VERSION ""

NS_ :

BS_:

BU_: NEO MCU GTW EPAS DI ESP SBW STW

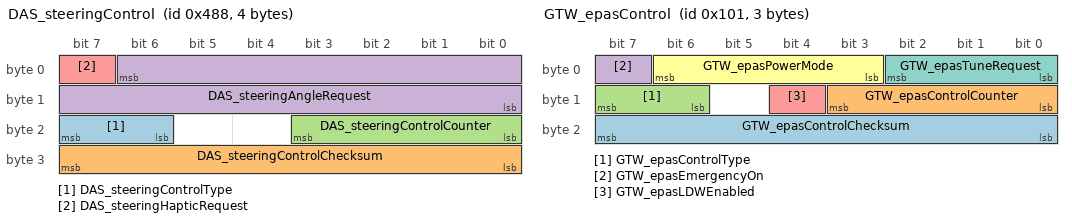
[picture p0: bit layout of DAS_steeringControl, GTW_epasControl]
BO_ 1160 DAS_steeringControl: 4 NEO
 SG_ DAS_steeringControlType : 23|2@0+ (1,0) [0|0] "" EPAS
 SG_ DAS_steeringControlChecksum : 31|8@0+ (1,0) [0|0] "" EPAS
 SG_ DAS_steeringControlCounter : 19|4@0+ (1,0) [0|0] "" EPAS
 SG_ DAS_steeringAngleRequest : 6|15@0+ (0.1,-1638.35) [-1638.35|1638.35] "deg" EPAS
 SG_ DAS_steeringHapticRequest : 7|1@0+ (1,0) [0|0] "" EPAS

BO_ 257 GTW_epasControl: 3 NEO
 SG_ GTW_epasControlChecksum : 23|8@0+ (1,0) [0|255] ""  NEO
 SG_ GTW_epasControlCounter : 11|4@0+ (1,0) [0|15] ""  NEO
 SG_ GTW_epasControlType : 15|2@0+ (1,0) [-1|4] ""  NEO
 SG_ GTW_epasEmergencyOn : 7|1@0+ (1,0) [-1|2] ""  NEO
 SG_ GTW_epasLDWEnabled : 12|1@0+ (1,0) [-1|2] ""  NEO
 SG_ GTW_epasPowerMode : 6|4@0+ (1,0) [4|14] ""  NEO
 SG_ GTW_epasTuneRequest : 2|3@0+ (1,0) [-1|8] ""  NEO

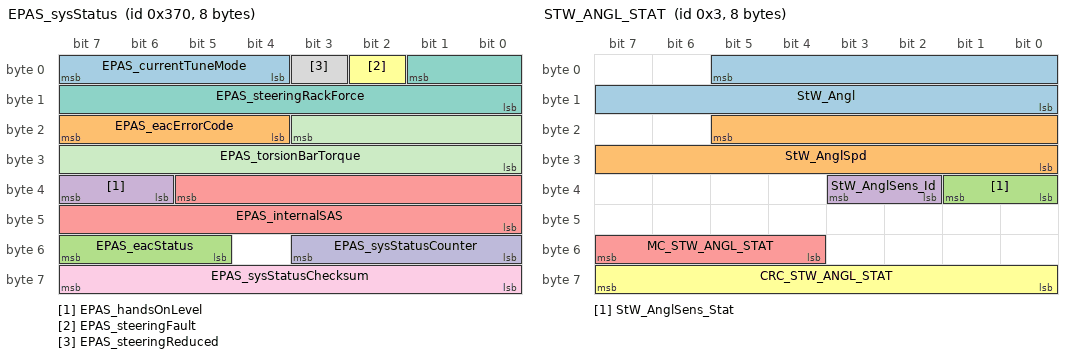
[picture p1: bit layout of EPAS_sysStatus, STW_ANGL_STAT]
BO_ 880 EPAS_sysStatus: 8 EPAS
 SG_ EPAS_currentTuneMode : 7|4@0+ (1,0) [8|15] ""  NEO
 SG_ EPAS_eacErrorCode : 23|4@0+ (1,0) [-1|16] ""  NEO
 SG_ EPAS_eacStatus : 55|3@0+ (1,0) [5|7] ""  NEO
 SG_ EPAS_handsOnLevel : 39|2@0+ (1,0) [-1|4] ""  NEO
 SG_ EPAS_internalSAS : 37|14@0+ (0.1,-819.200012) [0|0] "deg"  NEO
 SG_ EPAS_steeringFault : 2|1@0+ (1,0) [-1|2] ""  NEO
 SG_ EPAS_steeringRackForce : 1|10@0+ (50,-25575) [0|0] "N" NEO
 SG_ EPAS_steeringReduced : 3|1@0+ (1,0) [-1|2] ""  NEO
 SG_ EPAS_sysStatusChecksum : 63|8@0+ (1,0) [0|255] ""  NEO
 SG_ EPAS_sysStatusCounter : 51|4@0+ (1,0) [0|15] ""  NEO
 SG_ EPAS_torsionBarTorque : 19|12@0+ (0.01,-20.5) [0|0] "Nm"  NEO

BO_ 3 STW_ANGL_STAT: 8 STW
 SG_ StW_Angl : 5|14@0+ (0.5,-2048) [0|0] "deg"  NEO
 SG_ StW_AnglSpd : 21|14@0+ (0.5,-2048) [0|0] "/s"  NEO
 SG_ StW_AnglSens_Stat : 33|2@0+ (1,0) [-1|4] ""  NEO
 SG_ StW_AnglSens_Id : 35|2@0+ (1,0) [3|3] ""  NEO
 SG_ MC_STW_ANGL_STAT : 55|4@0+ (1,0) [0|15] ""  NEO
 SG_ CRC_STW_ANGL_STAT : 63|8@0+ (1,0) [0|255] ""  NEO

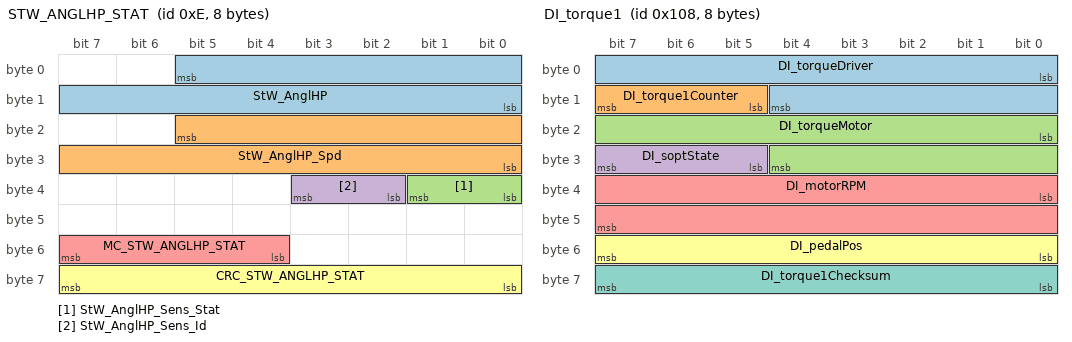
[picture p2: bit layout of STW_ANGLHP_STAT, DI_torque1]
BO_ 14 STW_ANGLHP_STAT: 8 STW
 SG_ StW_AnglHP : 5|14@0+ (0.1,-819.2) [-819.2|819] "deg"  NEO
 SG_ StW_AnglHP_Spd : 21|14@0+ (0.5,-4096) [-4096|4095.5] "deg/s"  NEO
 SG_ StW_AnglHP_Sens_Stat : 33|2@0+ (1,0) [0|0] ""  NEO
 SG_ StW_AnglHP_Sens_Id : 35|2@0+ (1,0) [0|0] ""  NEO
 SG_ MC_STW_ANGLHP_STAT : 55|4@0+ (1,0) [0|15] ""  NEO
 SG_ CRC_STW_ANGLHP_STAT : 63|8@0+ (1,0) [0|0] ""  NEO

BO_ 264 DI_torque1: 8 DI
 SG_ DI_torqueDriver : 0|13@1- (0.25,0) [-750|750] "Nm"  NEO
 SG_ DI_torque1Counter : 13|3@1+ (1,0) [0|0] ""  NEO
 SG_ DI_torqueMotor : 16|13@1- (0.25,0) [-750|750] "Nm"  NEO
 SG_ DI_soptState : 29|3@1+ (1,0) [0|0] ""  NEO
 SG_ DI_motorRPM : 32|16@1- (1,0) [-17000|17000] "RPM"  NEO
 SG_ DI_pedalPos : 48|8@1+ (0.4,0) [0|100] "%"  NEO
 SG_ DI_torque1Checksum : 56|8@1+ (1,0) [0|0] ""  NEO

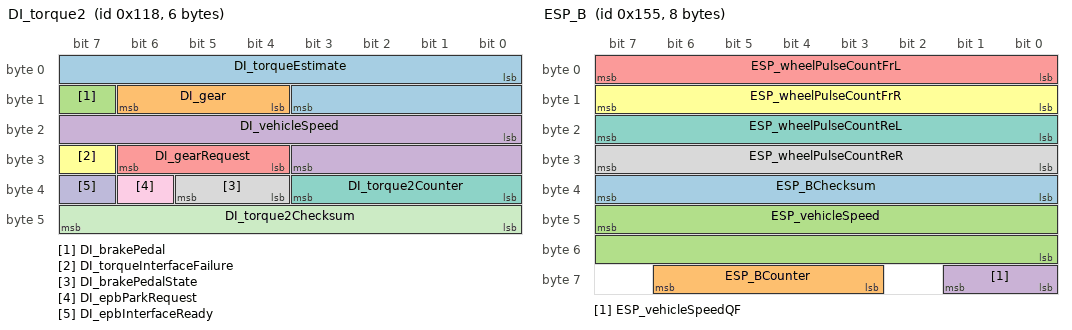
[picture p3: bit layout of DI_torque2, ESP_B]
BO_ 280 DI_torque2: 6 DI
 SG_ DI_torqueEstimate : 0|12@1- (0.5,0) [-750|750] "Nm" NEO
 SG_ DI_gear : 12|3@1+ (1,0) [0|0] "" NEO
 SG_ DI_brakePedal : 15|1@1+ (1,0) [0|0] "" NEO
 SG_ DI_vehicleSpeed : 16|12@1+ (0.05,-25) [-25|179.75] "MPH" NEO
 SG_ DI_gearRequest : 28|3@1+ (1,0) [0|0] "" NEO
 SG_ DI_torqueInterfaceFailure : 31|1@1+ (1,0) [0|0] "" NEO
 SG_ DI_torque2Counter : 32|4@1+ (1,0) [0|0] "" NEO
 SG_ DI_brakePedalState : 36|2@1+ (1,0) [0|0] "" NEO
 SG_ DI_epbParkRequest : 38|1@1+ (1,0) [0|0] "" NEO
 SG_ DI_epbInterfaceReady : 39|1@1+ (1,0) [0|0] "" NEO
 SG_ DI_torque2Checksum : 40|8@1+ (1,0) [0|0] "" NEO

BO_ 309 ESP_135h: 5 ESP
 SG_ ESP_135hChecksum : 23|8@0+ (1,0) [0|255] ""  NEO
 SG_ ESP_135hCounter : 11|4@0+ (1,0) [0|15] ""  NEO
 SG_ ESP_absBrakeEvent : 2|1@0+ (1,0) [-1|2] ""  NEO
 SG_ ESP_brakeDiscWipingActive : 4|1@0+ (1,0) [-1|2] ""  NEO
 SG_ ESP_brakeLamp : 3|1@0+ (1,0) [-1|2] ""  NEO
 SG_ ESP_espFaultLamp : 6|1@0+ (1,0) [-1|2] ""  NEO
 SG_ ESP_espLampFlash : 7|1@0+ (1,0) [-1|2] ""  NEO
 SG_ ESP_hillStartAssistActive : 1|2@0+ (1,0) [-1|4] ""  NEO
 SG_ ESP_messagePumpService : 24|1@0+ (1,0) [0|1] ""  NEO
 SG_ ESP_messagePumpFailure : 25|1@0+ (1,0) [0|1] ""  NEO
 SG_ ESP_messageEBDFailure : 26|1@0+ (1,0) [0|1] ""  NEO
 SG_ ESP_absFaultLamp : 27|1@0+ (1,0) [-1|2] ""  NEO
 SG_ ESP_tcDisabledByFault : 28|1@0+ (1,0) [0|1] ""  NEO
 SG_ ESP_messageDynoModeActive : 29|1@0+ (1,0) [0|1] ""  NEO
 SG_ ESP_hydraulicBoostEnabled : 30|1@0+ (1,0) [0|1] ""  NEO
 SG_ ESP_espOffLamp : 31|1@0+ (1,0) [-1|2] ""  NEO
 SG_ ESP_stabilityControlSts : 14|3@0+ (1,0) [6|7] ""  NEO
 SG_ ESP_tcLampFlash : 5|1@0+ (1,0) [-1|2] ""  NEO
 SG_ ESP_tcOffLamp : 15|1@0+ (1,0) [0|1] ""  NEO

BO_ 341 ESP_B: 8 ESP
 SG_ ESP_BChecksum : 39|8@0+ (1,0) [0|255] ""  NEO,EPAS
 SG_ ESP_BCounter : 62|4@0+ (1,0) [1|15] ""  NEO,EPAS
 SG_ ESP_vehicleSpeed : 47|16@0+ (0.00999999978,0) [0|0] "kph"  NEO,EPAS
 SG_ ESP_vehicleSpeedQF : 57|2@0+ (1,0) [1|2] ""  NEO,EPAS
 SG_ ESP_wheelPulseCountFrL : 7|8@0+ (1,0) [0|254] ""  NEO,EPAS
 SG_ ESP_wheelPulseCountFrR : 15|8@0+ (1,0) [0|254] ""  NEO,EPAS
 SG_ ESP_wheelPulseCountReL : 23|8@0+ (1,0) [0|254] ""  NEO,EPAS
 SG_ ESP_wheelPulseCountReR : 31|8@0+ (1,0) [0|254] ""  NEO,EPAS

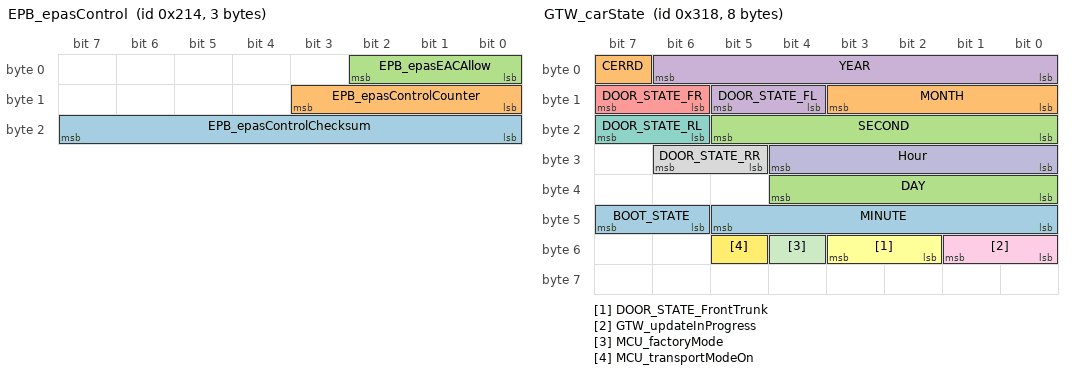
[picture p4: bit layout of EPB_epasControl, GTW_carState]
BO_ 532 EPB_epasControl: 3 EPB
 SG_ EPB_epasControlChecksum : 23|8@0+ (1,0) [0|255] ""  NEO,EPAS
 SG_ EPB_epasControlCounter : 11|4@0+ (1,0) [0|15] ""  NEO,EPAS
 SG_ EPB_epasEACAllow : 2|3@0+ (1,0) [4|7] ""  NEO,EPAS

BO_ 792 GTW_carState: 8 GTW
 SG_ BOOT_STATE : 47|2@0+ (1,0) [-1|4] ""  NEO
 SG_ CERRD : 7|1@0+ (1,0) [-1|2] ""  NEO
 SG_ DAY : 36|5@0+ (1,0) [2|31] ""  NEO
 SG_ DOOR_STATE_FL : 13|2@0+ (1,0) [-1|4] ""  NEO
 SG_ DOOR_STATE_FR : 15|2@0+ (1,0) [-1|4] ""  NEO
 SG_ DOOR_STATE_FrontTrunk : 51|2@0+ (1,0) [-1|4] ""  NEO
 SG_ DOOR_STATE_RL : 23|2@0+ (1,0) [-1|4] ""  NEO
 SG_ DOOR_STATE_RR : 30|2@0+ (1,0) [-1|4] ""  NEO
 SG_ GTW_updateInProgress : 49|2@0+ (1,0) [-1|4] ""  NEO
 SG_ Hour : 28|5@0+ (1,0) [0|29] "h"  NEO
 SG_ MCU_factoryMode : 52|1@0+ (1,0) [-1|2] ""  NEO
 SG_ MCU_transportModeOn : 53|1@0+ (1,0) [1|1] ""  NEO
 SG_ MINUTE : 45|6@0+ (1,0) [0|61] "min"  NEO
 SG_ MONTH : 11|4@0+ (1,0) [0|14] "Month"  NEO
 SG_ SECOND : 21|6@0+ (1,0) [0|61] "s"  NEO
 SG_ YEAR : 6|7@0+ (1,2000) [2000|2125] "Year"  NEO

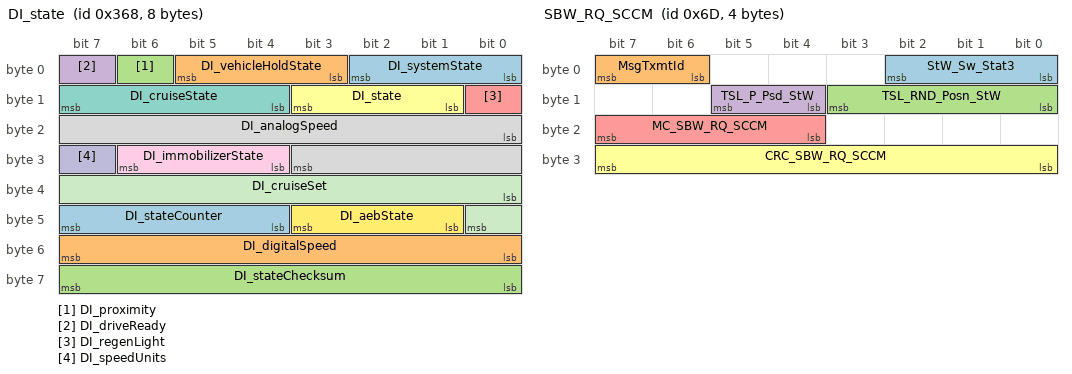
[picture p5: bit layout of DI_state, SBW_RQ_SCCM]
BO_ 872 DI_state: 8 DI
 SG_ DI_systemState : 0|3@1+ (1,0) [0|0] ""  NEO
 SG_ DI_vehicleHoldState : 3|3@1+ (1,0) [0|0] ""  NEO
 SG_ DI_proximity : 6|1@1+ (1,0) [0|0] ""  NEO
 SG_ DI_driveReady : 7|1@1+ (1,0) [0|0] ""  NEO
 SG_ DI_regenLight : 8|1@1+ (1,0) [0|0] ""  NEO
 SG_ DI_state : 9|3@1+ (1,0) [0|0] ""  NEO
 SG_ DI_cruiseState : 12|4@1+ (1,0) [0|0] ""  NEO
 SG_ DI_analogSpeed : 16|12@1+ (0.1,0) [0|150] "speed"  NEO
 SG_ DI_immobilizerState : 28|3@1+ (1,0) [0|0] ""  NEO
 SG_ DI_speedUnits : 31|1@1+ (1,0) [0|1] ""  NEO
 SG_ DI_cruiseSet : 32|9@1+ (0.5,0) [0|255.5] "speed"  NEO
 SG_ DI_aebState : 41|3@1+ (1,0) [0|0] ""  NEO
 SG_ DI_stateCounter : 44|4@1+ (1,0) [0|0] ""  NEO
 SG_ DI_digitalSpeed : 48|8@1+ (1,0) [0|250] ""  NEO
 SG_ DI_stateChecksum : 56|8@1+ (1,0) [0|0] ""  NEO

BO_ 109 SBW_RQ_SCCM: 4 STW
 SG_ StW_Sw_Stat3 : 0|3@1+ (1,0) [0|0] "" NEO
 SG_ MsgTxmtId : 6|2@1+ (1,0) [0|0] "" NEO
 SG_ TSL_RND_Posn_StW : 8|4@1+ (1,0) [0|0] "" NEO
 SG_ TSL_P_Psd_StW : 12|2@1+ (1,0) [0|0] "" NEO
 SG_ MC_SBW_RQ_SCCM : 20|4@1+ (1,0) [0|15] "" NEO
 SG_ CRC_SBW_RQ_SCCM : 24|8@1+ (1,0) [0|0] "" NEO

BO_ 69 STW_ACTN_RQ: 8 STW
 SG_ SpdCtrlLvr_Stat : 0|6@1+ (1,0) [0|0] "" NEO
 SG_ VSL_Enbl_Rq : 6|1@1+ (1,0) [0|0] "" NEO
 SG_ SpdCtrlLvrStat_Inv : 7|1@1+ (1,0) [0|0] "" NEO
 SG_ DTR_Dist_Rq : 8|8@1+ (1,0) [0|200] "" NEO
 SG_ TurnIndLvr_Stat : 16|2@1+ (1,0) [0|0] "" NEO
 SG_ HiBmLvr_Stat : 18|2@1+ (1,0) [0|0] "" NEO
 SG_ WprWashSw_Psd : 20|2@1+ (1,0) [0|0] "" NEO
 SG_ WprWash_R_Sw_Posn_V2 : 22|2@1+ (1,0) [0|0] "" NEO
 SG_ StW_Lvr_Stat : 24|3@1+ (1,0) [0|0] "" NEO
 SG_ StW_Cond_Flt : 27|1@1+ (1,0) [0|0] "" NEO
 SG_ StW_Cond_Psd : 28|2@1+ (1,0) [0|0] "" NEO
 SG_ HrnSw_Psd : 30|2@1+ (1,0) [0|0] "" NEO
 SG_ StW_Sw00_Psd : 32|1@1+ (1,0) [0|0] "" NEO
 SG_ StW_Sw01_Psd : 33|1@1+ (1,0) [0|0] "" NEO
 SG_ StW_Sw02_Psd : 34|1@1+ (1,0) [0|0] "" NEO
 SG_ StW_Sw03_Psd : 35|1@1+ (1,0) [0|0] "" NEO
 SG_ StW_Sw04_Psd : 36|1@1+ (1,0) [0|0] "" NEO
 SG_ StW_Sw05_Psd : 37|1@1+ (1,0) [0|0] "" NEO
 SG_ StW_Sw06_Psd : 38|1@1+ (1,0) [0|0] "" NEO
 SG_ StW_Sw07_Psd : 39|1@1+ (1,0) [0|0] "" NEO
 SG_ StW_Sw08_Psd : 40|1@1+ (1,0) [0|0] "" NEO
 SG_ StW_Sw09_Psd : 41|1@1+ (1,0) [0|0] "" NEO
 SG_ StW_Sw10_Psd : 42|1@1+ (1,0) [0|0] "" NEO
 SG_ StW_Sw11_Psd : 43|1@1+ (1,0) [0|0] "" NEO
 SG_ StW_Sw12_Psd : 44|1@1+ (1,0) [0|0] "" NEO
 SG_ StW_Sw13_Psd : 45|1@1+ (1,0) [0|0] "" NEO
 SG_ StW_Sw14_Psd : 46|1@1+ (1,0) [0|0] "" NEO
 SG_ StW_Sw15_Psd : 47|1@1+ (1,0) [0|0] "" NEO
 SG_ WprSw6Posn : 48|3@1+ (1,0) [0|0] "" NEO
 SG_ MC_STW_ACTN_RQ : 52|4@1+ (1,0) [0|15] "" NEO
 SG_ CRC_STW_ACTN_RQ : 56|8@1+ (1,0) [0|0] "" NEO

BO_ 643 BODY_R1: 8 GTW
 SG_ AirTemp_Insd : 47|8@0+ (0.25,0) [0|63.5] "C"  NEO
 SG_ AirTemp_Outsd : 63|8@0+ (0.5,-40) [-40|86.5] "C"  NEO
 SG_ Bckl_Sw_RL_Stat_SAM_R : 49|2@0+ (1,0) [-1|4] ""  NEO
 SG_ Bckl_Sw_RM_Stat_SAM_R : 53|2@0+ (1,0) [-1|4] ""  NEO
 SG_ Bckl_Sw_RR_Stat_SAM_R : 51|2@0+ (1,0) [-1|4] ""  NEO
 SG_ DL_RLtch_Stat : 9|2@0+ (1,0) [-1|4] ""  NEO
 SG_ DrRLtch_FL_Stat : 1|2@0+ (1,0) [-1|4] ""  NEO
 SG_ DrRLtch_FR_Stat : 3|2@0+ (1,0) [-1|4] ""  NEO
 SG_ DrRLtch_RL_Stat : 5|2@0+ (1,0) [-1|4] ""  NEO
 SG_ DrRLtch_RR_Stat : 7|2@0+ (1,0) [-1|4] ""  NEO
 SG_ EngHd_Stat : 11|2@0+ (1,0) [-1|4] ""  NEO
 SG_ LoBm_On_Rq : 32|1@0+ (1,0) [0|1] ""  NEO
 SG_ HiBm_On : 33|1@0+ (1,0) [0|1] ""  NEO
 SG_ Hrn_On : 26|1@0+ (1,0) [0|1] ""  NEO
 SG_ IrLmp_D_Lt_Flt : 34|1@0+ (1,0) [0|1] ""  NEO
 SG_ IrLmp_P_Rt_Flt : 35|1@0+ (1,0) [0|1] ""  NEO
 SG_ LgtSens_Twlgt : 18|3@0+ (1,0) [0|7] "Steps"  NEO
 SG_ LgtSens_SNA : 19|1@0+ (1,0) [0|1] ""  NEO
 SG_ LgtSens_Tunnel : 20|1@0+ (1,0) [0|1] ""  NEO
 SG_ LgtSens_Flt : 21|1@0+ (1,0) [0|1] ""  NEO
 SG_ LgtSens_Night : 22|1@0+ (1,0) [-1|2] ""  NEO
 SG_ ADL_LoBm_On_Rq : 23|1@0+ (1,0) [0|1] ""  NEO
 SG_ LoBm_D_Lt_Flt : 36|1@0+ (1,0) [0|1] ""  NEO
 SG_ LoBm_P_Rt_Flt : 37|1@0+ (1,0) [0|1] ""  NEO
 SG_ MPkBrk_Stat : 28|1@0+ (1,0) [-1|2] ""  NEO
 SG_ RevGr_Engg : 39|2@0+ (1,0) [-1|4] ""  NEO
 SG_ StW_Cond_Stat : 55|2@0+ (1,0) [-1|4] ""  NEO
 SG_ Term54_Actv : 27|1@0+ (1,0) [0|1] ""  NEO
 SG_ Trlr_Stat : 25|2@0+ (1,0) [-1|4] ""  NEO
 SG_ VTA_Alm_Actv : 13|1@0+ (1,0) [0|1] ""  NEO
 SG_ WprOutsdPkPosn : 29|1@0+ (1,0) [0|1] ""  NEO

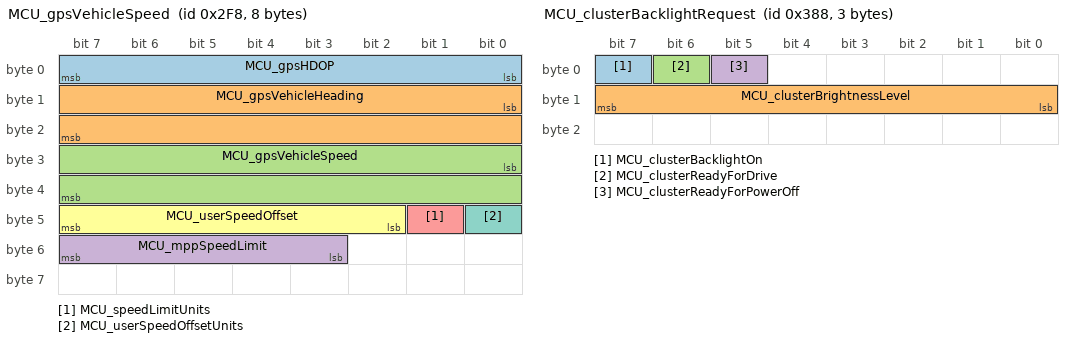
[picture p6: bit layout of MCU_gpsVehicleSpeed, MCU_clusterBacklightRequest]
BO_ 760 MCU_gpsVehicleSpeed: 8 MCU
 SG_ MCU_gpsHDOP : 0|8@1+ (0.1,0) [0|25.5] "1"  NEO
 SG_ MCU_gpsVehicleHeading : 8|16@1+ (0.00781,0) [0|511.82835] "deg"  NEO
 SG_ MCU_gpsVehicleSpeed : 24|16@1+ (0.00391,0) [0|256.24185] "km/hr"  NEO
 SG_ MCU_mppSpeedLimit : 51|5@1+ (5,0) [0|155] "kph/mph" NEO
 SG_ MCU_speedLimitUnits : 41|1@1+ (1,0) [-1|2] ""  NEO
 SG_ MCU_userSpeedOffset : 42|6@1+ (1,-30) [-30|33] "kph/mph" NEO
 SG_ MCU_userSpeedOffsetUnits : 40|1@1+ (1,0) [-1|2] ""  NEO

BO_ 904 MCU_clusterBacklightRequest: 3 NEO
 SG_ MCU_clusterBacklightOn : 7|1@1+ (1,0) [0|1] "" NEO
 SG_ MCU_clusterBrightnessLevel : 8|8@1+ (0.5,0) [0|127.5] "%" NEO
 SG_ MCU_clusterReadyForDrive : 6|1@1+ (1,0) [-1|2] ""  NEO
 SG_ MCU_clusterReadyForPowerOff : 5|1@1+ (1,0) [0|1] "" NEO

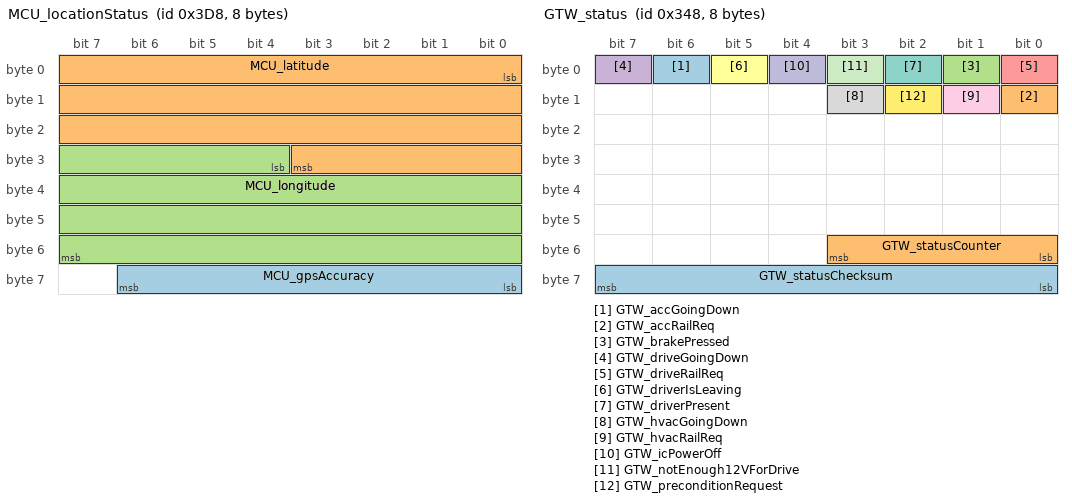
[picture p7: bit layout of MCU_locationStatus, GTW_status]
BO_ 984 MCU_locationStatus: 8 MCU
 SG_ MCU_gpsAccuracy : 56|7@1+ (0.200000003,0) [0|25.200000378] "m" NEO
 SG_ MCU_latitude : 0|28@1- (1E-006,0) [-134.217727597347|134.217726597347] "deg"  NEO
 SG_ MCU_longitude : 28|28@1- (1E-006,0) [-268.435455194694|268.435454194694] "deg"  NEO

BO_ 840 GTW_status: 8 GTW
 SG_ GTW_accGoingDown : 6|1@0+ (1,0) [0|1] ""  NEO
 SG_ GTW_accRailReq : 8|1@0+ (1,0) [0|1] ""  NEO
 SG_ GTW_brakePressed : 1|1@0+ (1,0) [0|1] ""  NEO
 SG_ GTW_driveGoingDown : 7|1@0+ (1,0) [0|1] ""  NEO
 SG_ GTW_driveRailReq : 0|1@0+ (1,0) [0|1] ""  NEO
 SG_ GTW_driverIsLeaving : 5|1@0+ (1,0) [0|1] ""  NEO
 SG_ GTW_driverPresent : 2|1@0+ (1,0) [0|1] ""  NEO
 SG_ GTW_hvacGoingDown : 11|1@0+ (1,0) [0|1] ""  NEO
 SG_ GTW_hvacRailReq : 9|1@0+ (1,0) [0|1] ""  NEO
 SG_ GTW_icPowerOff : 4|1@0+ (1,0) [0|1] ""  NEO
 SG_ GTW_notEnough12VForDrive : 3|1@0+ (1,0) [0|1] ""  NEO
 SG_ GTW_preconditionRequest : 10|1@0+ (1,0) [0|1] ""  NEO
 SG_ GTW_statusChecksum : 63|8@0+ (1,0) [0|255] ""  NEO
 SG_ GTW_statusCounter : 51|4@0+ (1,0) [0|15] ""  NEO
